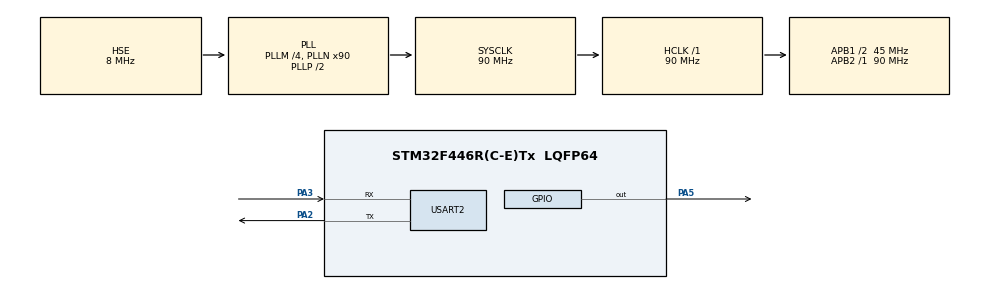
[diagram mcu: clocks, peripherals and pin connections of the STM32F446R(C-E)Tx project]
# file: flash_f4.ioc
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Mcu.Family=STM32F4
Mcu.Name=STM32F446R(C-E)Tx
Mcu.Package=LQFP64
NVIC.PriorityGroup=NVIC_PRIORITYGROUP_4
PA2.Mode=Asynchronous
PA2.Signal=USART2_TX
PA3.Mode=Asynchronous
PA3.Signal=USART2_RX
PA5.Signal=GPIO_Output
PH0-OSC_IN.Mode=HSE-External-Oscillator
PH0-OSC_IN.Signal=RCC_OSC_IN
PH1-OSC_OUT.Mode=HSE-External-Oscillator
PH1-OSC_OUT.Signal=RCC_OSC_OUT
ProjectManager.HeapSize=0x200
ProjectManager.StackSize=0x400
ProjectManager.TargetToolchain=SW4STM32
RCC.AHBFreq_Value=90000000
RCC.APB1CLKDivider=RCC_HCLK_DIV2
RCC.APB1Freq_Value=45000000
RCC.APB1TimFreq_Value=90000000
RCC.APB2Freq_Value=90000000
RCC.APB2TimFreq_Value=90000000
RCC.CortexFreq_Value=90000000
RCC.HCLKFreq_Value=90000000
RCC.HSE_VALUE=8000000
RCC.PLLM=4
RCC.PLLN=90
RCC.PLLSourceVirtual=RCC_PLLSOURCE_HSE
RCC.SYSCLKFreq_VALUE=90000000
RCC.SYSCLKSource=RCC_SYSCLKSOURCE_PLLCLK
RCC.USBFreq_Value=90000000
RCC.VCOOutputFreq_Value=180000000
USART2.VirtualMode=VM_ASYNC
board=custom

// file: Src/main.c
/**
  ******************************************************************************
  * @file           : main.c
  * @brief          : Main program body
  ******************************************************************************
  ** This notice applies to any and all portions of this file
  * that are not between comment pairs USER CODE BEGIN and
  * USER CODE END. Other portions of this file, whether
  * inserted by the user or by software development tools
  * are owned by their respective copyright owners.
  *
  * COPYRIGHT(c) 2019 STMicroelectronics
  *
  * Redistribution and use in source and binary forms, with or without modification,
  * are permitted provided that the following conditions are met:
  *   1. Redistributions of source code must retain the above copyright notice,
  *      this list of conditions and the following disclaimer.
  *   2. Redistributions in binary form must reproduce the above copyright notice,
  *      this list of conditions and the following disclaimer in the documentation
  *      and/or other materials provided with the distribution.
  *   3. Neither the name of STMicroelectronics nor the names of its contributors
  *      may be used to endorse or promote products derived from this software
  *      without specific prior written permission.
  *
  * THIS SOFTWARE IS PROVIDED BY THE COPYRIGHT HOLDERS AND CONTRIBUTORS "AS IS"
  * AND ANY EXPRESS OR IMPLIED WARRANTIES, INCLUDING, BUT NOT LIMITED TO, THE
  * IMPLIED WARRANTIES OF MERCHANTABILITY AND FITNESS FOR A PARTICULAR PURPOSE ARE
  * DISCLAIMED. IN NO EVENT SHALL THE COPYRIGHT HOLDER OR CONTRIBUTORS BE LIABLE
  * FOR ANY DIRECT, INDIRECT, INCIDENTAL, SPECIAL, EXEMPLARY, OR CONSEQUENTIAL
  * DAMAGES (INCLUDING, BUT NOT LIMITED TO, PROCUREMENT OF SUBSTITUTE GOODS OR
  * SERVICES; LOSS OF USE, DATA, OR PROFITS; OR BUSINESS INTERRUPTION) HOWEVER
  * CAUSED AND ON ANY THEORY OF LIABILITY, WHETHER IN CONTRACT, STRICT LIABILITY,
  * OR TORT (INCLUDING NEGLIGENCE OR OTHERWISE) ARISING IN ANY WAY OUT OF THE USE
  * OF THIS SOFTWARE, EVEN IF ADVISED OF THE POSSIBILITY OF SUCH DAMAGE.
  *
  ******************************************************************************
  */
#include "main.h"
#include "stm32f4xx_hal.h"
#include "usart.h"
#include "gpio.h"

/* USER CODE BEGIN Includes */
#include "stm32f4xx_hal_flash_ex.h"
#include "stm32f4xx_hal_flash_ramfunc.h"
#include "stm32f4xx_hal_flash.h"
#include "string.h"
#include <time.h>
/* USER CODE END Includes */

/* USER CODE BEGIN PV */
#define FLASH_START_ADDRESS   ((uint32_t)0x08040000)
#define size 					1*1024
UART_HandleTypeDef huart2;
uint32_t buffer[size];
uint32_t buffer_read[size];

__attribute__((__section__(".user_data"))) const char userConfig[64];
/* Private variables ---------------------------------------------------------*/

/* USER CODE END PV */

void SystemClock_Config(void);

/* USER CODE BEGIN PFP */
/* Private function prototypes -----------------------------------------------*/

void Flash_Write(uint32_t Flash_Address, uint32_t Flash_Data);
uint32_t Flash_Read(uint32_t Flash_Address);
void Flash_Write_Block(uint32_t* buffer, uint16_t length);

/* USER CODE END PFP */

int main(void)
{

  /* MCU Configuration----------------------------------------------------------*/

  /* Reset of all peripherals, Initializes the Flash interface and the Systick. */
  HAL_Init();

  /* Configure the system clock */
  SystemClock_Config();

  /* Initialize all configured peripherals */
  MX_GPIO_Init();
  MX_USART2_UART_Init();

  /* USER CODE BEGIN 2 */
  //initialize buffer
  for (int i = 0; i<size; i++){
	  buffer[i] = i;
  }

  //Flash_Write_Block(buffer, size); //write to flash

  //Flash_Write_Block(buffer, size);

  //read from flash
  for (int i = 0; i< size; i++){
	  buffer_read[i] = Flash_Read(FLASH_START_ADDRESS+i*4);
  }

  /*****bench mark the time ************************************
	//doesnt work
  //erase one sector: 16Kb

  HAL_FLASH_Unlock();
  int erase_start = HAL_GetTick();
  FLASH_Erase_Sector(FLASH_SECTOR_6, VOLTAGE_RANGE_3);
  int erase_end = HAL_GetTick();
  HAL_FLASH_Lock();

  int erase_duration = erase_end - erase_start;
  char erase_time[16];
  sprintf(erase_time, "%d", erase_duration);
  HAL_UART_Transmit(&huart2, (unsigned char*)"erase 16Kb:\n", 11, 1000);
  HAL_UART_Transmit(&huart2, (unsigned char*)erase_time, 16, 1000); //print the erase duration

  //write to sector
  int write_start = HAL_GetTick();
  Flash_Write_Block(buffer, size);
  int write_end = HAL_GetTick();
  int write_duration = write_end - write_start;
  char write_time[16];
  sprintf(write_time, "%d", write_duration);
  HAL_UART_Transmit(&huart2, (unsigned char*)"write 1Kb:\n", 10, 1000);
  HAL_UART_Transmit(&huart2, (unsigned char*)write_time, 16, 1000);
  //****************************************************************
	*/
  /* USER CODE END 2 */

  /* Infinite loop */
  /* USER CODE BEGIN WHILE */
  while (1)
  {
	  /*
	  //test HAL_tick()*******************************
	  int start = HAL_GetTick();
	  HAL_Delay(500);
	  int end = HAL_GetTick();
	  char buffer_time[16];
	  int duration = end - start;
	  sprintf(buffer_time, "%d", duration);
	  //HAL_UART_Transmit(&huart2, (unsigned char*)"start\n", 5, 1000);
	  HAL_UART_Transmit(&huart2, (unsigned char *)buffer_time, 4, 1000);
	  //***********************************************************
	  */

	  HAL_GPIO_WritePin(GPIOA, GPIO_PIN_5, GPIO_PIN_SET);
	  Flash_Write_Block(buffer, size); //comment out
	  //Flash_Write(FLASH_START_ADDRESS, 0);
	  //HAL_FLASH_Unlock();
	  //FLASH_Erase_Sector(FLASH_SECTOR_6, VOLTAGE_RANGE_3);
	  //HAL_FLASH_Lock();
	  HAL_GPIO_WritePin(GPIOA, GPIO_PIN_5, GPIO_PIN_RESET);
	  //Flash_Write(FLASH_START_ADDRESS, 0);
	  Flash_Write_Block(buffer, size);
	  //HAL_FLASH_Unlock();
	  //FLASH_Erase_Sector(FLASH_SECTOR_6, VOLTAGE_RANGE_3);
	  //HAL_FLASH_Lock();

	  //buffer[0] = 3;
	  uint16_t flag = 0;
	  for (int i = 0; i< size; i++){
		  if (buffer_read[i] == buffer[i]){
			  flag++;
		  }
	  }

	  //test
	  if (flag == size){
		  HAL_UART_Transmit(&huart2, (unsigned char *) "valid\n", 5, 1000);
	  }
	  else{
		  HAL_UART_Transmit(&huart2, (unsigned char *) "invalid\n", 8, 1000);
	  }

  /* USER CODE END WHILE */

  }

}

void SystemClock_Config(void)
{

  RCC_OscInitTypeDef RCC_OscInitStruct;
  RCC_ClkInitTypeDef RCC_ClkInitStruct;

    /**Configure the main internal regulator output voltage
    */
  __HAL_RCC_PWR_CLK_ENABLE();

  __HAL_PWR_VOLTAGESCALING_CONFIG(PWR_REGULATOR_VOLTAGE_SCALE3);

    /**Initializes the CPU, AHB and APB busses clocks
    */
  RCC_OscInitStruct.OscillatorType = RCC_OSCILLATORTYPE_HSE;
  RCC_OscInitStruct.HSEState = RCC_HSE_ON;
  RCC_OscInitStruct.PLL.PLLState = RCC_PLL_ON;
  RCC_OscInitStruct.PLL.PLLSource = RCC_PLLSOURCE_HSE;
  RCC_OscInitStruct.PLL.PLLM = 4;
  RCC_OscInitStruct.PLL.PLLN = 90;
  RCC_OscInitStruct.PLL.PLLP = RCC_PLLP_DIV2;
  RCC_OscInitStruct.PLL.PLLQ = 2;
  RCC_OscInitStruct.PLL.PLLR = 2;
  if (HAL_RCC_OscConfig(&RCC_OscInitStruct) != HAL_OK)
  {
    _Error_Handler(__FILE__, __LINE__);
  }

    /**Initializes the CPU, AHB and APB busses clocks
    */
  RCC_ClkInitStruct.ClockType = RCC_CLOCKTYPE_HCLK|RCC_CLOCKTYPE_SYSCLK
                              |RCC_CLOCKTYPE_PCLK1|RCC_CLOCKTYPE_PCLK2;
  RCC_ClkInitStruct.SYSCLKSource = RCC_SYSCLKSOURCE_PLLCLK;
  RCC_ClkInitStruct.AHBCLKDivider = RCC_SYSCLK_DIV1;
  RCC_ClkInitStruct.APB1CLKDivider = RCC_HCLK_DIV2;
  RCC_ClkInitStruct.APB2CLKDivider = RCC_HCLK_DIV1;

  if (HAL_RCC_ClockConfig(&RCC_ClkInitStruct, FLASH_LATENCY_2) != HAL_OK)
  {
    _Error_Handler(__FILE__, __LINE__);
  }

    /**Configure the Systick interrupt time
    */
  HAL_SYSTICK_Config(HAL_RCC_GetHCLKFreq()/1000);

    /**Configure the Systick
    */
  HAL_SYSTICK_CLKSourceConfig(SYSTICK_CLKSOURCE_HCLK);

  /* SysTick_IRQn interrupt configuration */
  HAL_NVIC_SetPriority(SysTick_IRQn, 0, 0);
}

/* USER CODE BEGIN 4 */
void Flash_Write(uint32_t Flash_Address, uint32_t Flash_Data){
	HAL_FLASH_Unlock();
    __HAL_FLASH_CLEAR_FLAG(FLASH_FLAG_EOP | FLASH_FLAG_OPERR | FLASH_FLAG_WRPERR | FLASH_FLAG_PGAERR | FLASH_FLAG_PGSERR );
    FLASH_Erase_Sector(FLASH_SECTOR_6, VOLTAGE_RANGE_3);
	HAL_FLASH_Program(FLASH_TYPEPROGRAM_WORD, Flash_Address,Flash_Data);  //&userConfig[index] ////////comment
	HAL_FLASH_Lock();
}

uint32_t Flash_Read(uint32_t Flash_Address){
	uint32_t Flash_Data;
	Flash_Data = *(uint32_t*) Flash_Address;
	return Flash_Data;
}

void Flash_Write_Block(uint32_t* buffer, uint16_t length){
	   HAL_FLASH_Unlock();
	   __HAL_FLASH_CLEAR_FLAG(FLASH_FLAG_EOP | FLASH_FLAG_OPERR | FLASH_FLAG_WRPERR | FLASH_FLAG_PGAERR | FLASH_FLAG_PGSERR );
	   FLASH_Erase_Sector(FLASH_SECTOR_6, VOLTAGE_RANGE_3);
	   for (int i = 0; i< length; i++){
		   uint32_t address = FLASH_START_ADDRESS + i*4;
		   HAL_FLASH_Program(FLASH_TYPEPROGRAM_WORD, address,buffer[i]);  //&userConfig[index]
	   }
	   HAL_FLASH_Lock();
}

/*
uint32_t Flash_Read_Block(uint32_t length){
    uint32_t val[length];
    address = length + FLASH_START_ADDRESS;
    val = *(uint32_t*)address;
    return val;
}
*/

/* USER CODE END 4 */

void _Error_Handler(char *file, int line)
{
  while(1)
  {
  }
}

/************************ (C) COPYRIGHT STMicroelectronics *****END OF FILE****/
